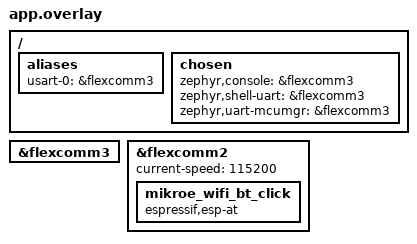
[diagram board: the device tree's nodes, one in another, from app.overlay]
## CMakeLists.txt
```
# SPDX-License-Identifier: Apache-2.0

add_compile_definitions(IS_ZEPHYR)

cmake_minimum_required(VERSION 3.20.0)
find_package(Zephyr REQUIRED HINTS $ENV{ZEPHYR_BASE})
project(dhcpv4_client)

file(GLOB_RECURSE app_sources src/*.c)

target_sources(app PRIVATE ${app_sources})

target_include_directories(app PRIVATE
    ${CMAKE_CURRENT_SOURCE_DIR}/src
    ${CMAKE_CURRENT_SOURCE_DIR}/src/common
    ${CMAKE_CURRENT_SOURCE_DIR}/src/pufcaller
    ${CMAKE_CURRENT_SOURCE_DIR}/src/pufcaller/crosscon_hv
    ${CMAKE_CURRENT_SOURCE_DIR}/src/pufcaller/crosscon_hv/crosscon_hv_tee
)

# Optional: define HAS_LOCAL_WIFI_CONFIG if wifi_config_local.h exists
if(EXISTS "${CMAKE_CURRENT_SOURCE_DIR}/src/wifi_config_local.h")
    add_compile_definitions(HAS_LOCAL_WIFI_CONFIG=1)
endif()
```

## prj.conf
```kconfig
# Kernel options
# CONFIG_MAIN_STACK_SIZE=16384
CONFIG_MAIN_STACK_SIZE=8192
CONFIG_ENTROPY_GENERATOR=y
CONFIG_INIT_STACKS=y
# CONFIG_COMMON_LIBC_MALLOC_ARENA_SIZE=8192
CONFIG_COMMON_LIBC_MALLOC_ARENA_SIZE=4096

# General config
CONFIG_NEWLIB_LIBC=y

# Networking config
CONFIG_NETWORKING=y
CONFIG_NET_IPV6=n
CONFIG_NET_IPV4=y
CONFIG_NET_ARP=y
CONFIG_NET_UDP=y
CONFIG_NET_TCP=y
CONFIG_NET_DHCPV4=y
CONFIG_NET_DHCPV4_OPTION_CALLBACKS=y

CONFIG_NET_MGMT=y
CONFIG_NET_MGMT_EVENT=y
CONFIG_NET_MGMT_EVENT_INFO=y

# Network debug config
CONFIG_LOG=y
CONFIG_NET_LOG=n
CONFIG_NET_SOCKETS_LOG_LEVEL_DBG=n
CONFIG_NET_HTTP_LOG_LEVEL_DBG=n
CONFIG_NET_IPV6_LOG_LEVEL_DBG=n
CONFIG_NET_IPV6_ND_LOG_LEVEL_DBG=n

CONFIG_SLIP_STATISTICS=n
CONFIG_NET_SHELL=n

# WiFi
CONFIG_WIFI=y
CONFIG_WIFI_ESP_AT=y
CONFIG_WIFI_ESP_AT_VERSION_2_0=y
CONFIG_NET_L2_WIFI_MGMT=y

# Sockets
CONFIG_NET_SOCKETS=y
CONFIG_ZVFS_POLL_MAX=4
CONFIG_POSIX_API=y

# TLS configuration
CONFIG_WOLFSSL=y
CONFIG_WOLFSSL_BUILTIN=y

# Debug
# CONFIG_LOG_DEFAULT_LEVEL=4
# CONFIG_KERNEL_LOG_LEVEL_OFF=y

# ## UART log backend
# CONFIG_LOG_BACKEND_UART=y
```

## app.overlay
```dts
/ {
	aliases{
		usart-0 = &flexcomm3;
	};

	chosen {
		zephyr,console = &flexcomm3;
		zephyr,shell-uart = &flexcomm3;
		zephyr,uart-mcumgr = &flexcomm3;
	};
};

&flexcomm3 {
	status = "okay";
};

&flexcomm2 {
	status = "okay";
	current-speed = <115200>;

	mikroe_wifi_bt_click {
		compatible = "espressif,esp-at";
		status = "okay";
	};
};
```

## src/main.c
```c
/* Networking DHCPv4 client */

/*
 * Copyright (c) 2025 3mdeb Sp z o.o.
 *
 * SPDX-License-Identifier: Apache-2.0
 */

#include "pufcaller/pufcaller.h"
#include <stdint.h>
#include <string.h>
#include <zephyr/logging/log.h>

LOG_MODULE_REGISTER(MAIN);

#include <zephyr/kernel.h>
#include <zephyr/linker/sections.h>
#include <stdio.h>

#include <zephyr/net/net_context.h>
#include <zephyr/net/net_core.h>
#include <zephyr/net/net_if.h>
#include <zephyr/net/net_mgmt.h>

#include <zephyr/net/wifi.h>
#include <zephyr/net/wifi_mgmt.h>

/* socket */
#include <zephyr/net/net_ip.h>
#include <zephyr/net/socket.h>

/* pufcaller */
#include "pufcaller/pufcaller.h"
#include "common/challenge.h"

/* SSL */
#ifndef WOLFSSL_USER_SETTINGS
    #include <wolfssl/options.h>
#endif
#include <wolfssl/ssl.h>
#include "ssl_certs.h"
#define HEAP_HINT  NULL

#define DHCP_OPTION_NTP (42)
#define MACSTR "%02X:%02X:%02X:%02X:%02X:%02X"

static uint8_t ntp_server[4];

static struct net_mgmt_event_callback mgmt_cb;

static struct net_dhcpv4_option_callback dhcp_cb;

func_call_t        initCh;
func_call_t        commCh;
func_call_t        proofsCh;

/*********** Socket start ***********/

#define SERVER_ADDR  "192.168.10.139"
#define SERVER_PORT  12345

/* DO NOT use this in production. You should implement a way
 * to get the current date. */
static int verifyIgnoreDateError(int preverify, WOLFSSL_X509_STORE_CTX* store)
{
    if (store->error == ASN_BEFORE_DATE_E)
        return 1; /* override error */
    else
        return preverify;
}

static int test_socket_connection(void) {
  struct sockaddr_in servAddr;
  int                ret;
  int                sock;
  char               buff[256];
  size_t             len;
  const char msg[] = "Hello from Zephyr!\n";
  char               wolfsslErrorStr[80];

  /* declare wolfSSL objects */
  WOLFSSL_CTX* ctx;
  WOLFSSL*     ssl;
  WOLFSSL_CIPHER* cipher;

  LOG_INF("Creating socket...");

  /* Create a socket that uses an internet IPv4 address,
   * Sets the socket to be stream based (TCP) */
	sock = socket(AF_INET, SOCK_STREAM, IPPROTO_TCP);

	if (sock < 0) {
		LOG_ERR("Failed to create HTTP socket (%d)", -errno);
	}

  LOG_INF("Socket created successfuly");

  /* Initialize the server address struct with zeros */
	memset(&servAddr, 0, sizeof(servAddr));
  LOG_DBG("memset");

  /* Fill in the server address */
  servAddr.sin_family = AF_INET;             /* using IPv4      */
  servAddr.sin_port   = htons(SERVER_PORT);  /* on SERVER_PORT  */
  LOG_DBG("server settings");

	if (inet_pton(AF_INET, SERVER_ADDR, &servAddr.sin_addr) != 1) {
	  LOG_ERR("Invalid server address");
	  ret = -1;
	}

  /* Connect to the server */
  LOG_INF("Connecting to the server...");
  if ((ret = connect(sock, (struct sockaddr*) &servAddr, sizeof(servAddr)))
       == -1) {
      LOG_ERR("Failed to connect");
      goto end;
  }

  /*---------------------------------*/
  /* Start of wolfSSL initialization and configuration */
  /*---------------------------------*/
  /* Initialize wolfSSL */
  LOG_DBG("wolfssl init");
  if ((ret = wolfSSL_Init()) != WOLFSSL_SUCCESS) {
      fprintf(stderr, "ERROR: Failed to initialize the library\n");
      goto socket_cleanup;
  }

#ifdef DEBUG_WOLFSSL
    wolfSSL_Debugging_ON();
#endif

  LOG_DBG("wolfssl ctx");
  /* Create and initialize WOLFSSL_CTX */
#ifdef USE_TLSV13
  LOG_DBG("Using TLS v1.3");
  ctx = wolfSSL_CTX_new_ex(wolfTLSv1_3_client_method_ex(HEAP_HINT), HEAP_HINT);
#else
  LOG_INF("Using TLS v1.2");
  ctx = wolfSSL_CTX_new_ex(wolfTLSv1_2_client_method_ex(HEAP_HINT), HEAP_HINT);
#endif
  if (ctx == NULL) {
    LOG_ERR("Failed to create WOLFSSL_CTX");
    ret = -1;
    goto socket_cleanup;
  }

  LOG_INF("Setting up cipher list...");
  if (wolfSSL_CTX_set_cipher_list(ctx, "ECDHE-ECDSA-AES256-GCM-SHA384") != WOLFSSL_SUCCESS) {
        fprintf(stderr, "Failed to set cipher list\n");
        ret = -1;
        goto ctx_cleanup;
    }

  /* Load client certificate into WOLFSSL_CTX */
  LOG_INF("Loading client certificate...");
  if ((ret = wolfSSL_CTX_use_certificate_buffer(ctx, client_cert_der,
               client_cert_der_len, WOLFSSL_FILETYPE_ASN1)) != WOLFSSL_SUCCESS) {
    LOG_ERR("Failed to load client certificate.");
    goto ctx_cleanup;
  }

  /* Load client key into WOLFSSL_CTX */
  LOG_INF("Loading client key...");
  if ((ret = wolfSSL_CTX_use_PrivateKey_buffer(ctx, client_key_der,
               client_key_der_len, WOLFSSL_FILETYPE_ASN1)) != WOLFSSL_SUCCESS) {
    LOG_ERR("Failed to load client key.");
    goto ctx_cleanup;
  }

  /* Load CA certificate into WOLFSSL_CTX for validating peer */
  LOG_INF("Loading CA certificate...");
  if ((ret = wolfSSL_CTX_load_verify_buffer_ex(ctx, ca_cert_der,
          ca_cert_der_len, WOLFSSL_FILETYPE_ASN1, 0,
          /* DO NOT use this in production. You should
           * implement a way to get the current date. */
          WOLFSSL_LOAD_FLAG_DATE_ERR_OKAY)) !=
          WOLFSSL_SUCCESS) {
    LOG_ERR("Failed to load CA certificate.");
    goto ctx_cleanup;
  }

  /* validate peer certificate */
  wolfSSL_CTX_set_verify(ctx,
    WOLFSSL_VERIFY_PEER|WOLFSSL_VERIFY_FAIL_IF_NO_PEER_CERT,
    verifyIgnoreDateError);

  /* Create a WOLFSSL object */
  LOG_INF("Creating SSL object...");
  if ((ssl = wolfSSL_new(ctx)) == NULL) {
      LOG_ERR("Failed to create WOLFSSL object");
      ret = -1;
      goto ctx_cleanup;
  }

  /* Attach wolfSSL to the socket */
  LOG_INF("Attaching SSL object...");
  if ((ret = wolfSSL_set_fd(ssl, sock)) != WOLFSSL_SUCCESS) {
      LOG_ERR("Failed to set the file descriptor");
      goto cleanup;
  }

  /* Connect to wolfSSL on the server side */
  LOG_INF("Connecting to server...");
  if ((ret = wolfSSL_connect(ssl)) != WOLFSSL_SUCCESS) {
      wolfSSL_ERR_error_string(wolfSSL_get_error(ssl, ret), wolfsslErrorStr);
      LOG_ERR("Failed to connect to server: %s", wolfsslErrorStr);
      goto cleanup;
  }

  cipher = wolfSSL_get_current_cipher(ssl);
  LOG_INF("SSL cipher suite is: %s", wolfSSL_CIPHER_get_name(cipher));

  if (initFunc(&initCh, PUF_TA_INIT_FUNC_ID, pattern_init_commit))
    LOG_ERR("Failed to allocate memory for the init...");
  LOG_DBG("Receiving init");
  if (recChallenge(ssl, &initCh))
    LOG_ERR("Failed to receive init!");

  if (initFunc(&commCh, PUF_TA_GET_COMMITMENT_FUNC_ID, pattern_init_commit))
    LOG_ERR("Failed to allocate memory for the commitment...");
  LOG_DBG("Receiving commitment");
  if (recChallenge(ssl, &commCh))
    LOG_ERR("Failed to receive commitment!");

  if (initFunc(&proofsCh, PUF_TA_GET_ZK_PROOFS_FUNC_ID, pattern_proofs))
    LOG_ERR("Failed to allocate memory for the proofs...");
  LOG_DBG("Receiving proofs");
  if (recChallenge(ssl, &proofsCh))
    LOG_ERR("Failed to receive proofs!");

  LOG_INF("Challenging the PUF");
  challenge_puf(&initCh, &commCh, &proofsCh);

  LOG_INF("Sending init response");
  if (sendResponse(ssl, &initCh)) {
    LOG_INF("Sending init response failed");
    goto cleanup;
  }

  LOG_INF("Sending commitment response");
  if (sendResponse(ssl, &commCh)) {
    LOG_INF("Sending commitment response failed");
    goto cleanup;
  }

  LOG_INF("Sending proofs response");
  if (sendResponse(ssl, &proofsCh)) {
    LOG_INF("Sending proofs response failed");
    goto cleanup;
  }

  /* Construct a message for the server */
  LOG_INF("Constructing message for server...");
  memset(buff, 0, sizeof(buff));
  memcpy(buff, msg, sizeof(msg));
  len = strnlen(buff, sizeof(buff));

  /* Send the message to the server */
  LOG_INF("Sending message to server...");
  if ((ret = wolfSSL_write(ssl, buff, len)) != len) {
      LOG_ERR("Failed to write entire message");
      LOG_ERR("%d bytes of %d bytes were sent", ret, (int) len);
      goto cleanup;
  }

  /* Read the server data into our buff array */
  LOG_INF("Reading message from server...");
  memset(buff, 0, sizeof(buff));
  if ((ret = wolfSSL_read(ssl, buff, sizeof(buff)-1)) == -1) {
      LOG_ERR("Failed to read from server");
      goto cleanup;
  }

  /* Print to stdout any data the server sends */
  LOG_INF("Received from server: %s", buff);

  /* Bidirectional shutdown */
  LOG_INF("Starting SSL shutdown...");
  while (wolfSSL_shutdown(ssl) == WOLFSSL_SHUTDOWN_NOT_DONE) {
      LOG_INF("SSL shutdown not complete");
  }

  LOG_INF("SSL shutdown complete");

  ret = 0;

  /* Cleanup and return */
cleanup:
  wolfSSL_free(ssl);      /* Free the wolfSSL object                  */
  freeFunc(&initCh);
  freeFunc(&commCh);
  freeFunc(&proofsCh);
ctx_cleanup:
  wolfSSL_CTX_free(ctx);  /* Free the wolfSSL context object          */
  wolfSSL_Cleanup();      /* Cleanup the wolfSSL environment          */
socket_cleanup:
  close(sock)    ;          /* Close the connection to the server       */
end:
  LOG_DBG("ret: %d", ret);
  return ret;               /* Return reporting a success               */
}

/*********** Socket end ***********/

/* Wi-Fi Configuration */
#include "wifi_config.h"
#define WIFI_SECURITY_TYPE WIFI_SECURITY_TYPE_PSK

#define NET_EVENT_WIFI_MASK                                                    \
  (NET_EVENT_WIFI_CONNECT_RESULT | NET_EVENT_WIFI_DISCONNECT_RESULT |          \
   NET_EVENT_WIFI_AP_ENABLE_RESULT | NET_EVENT_WIFI_AP_DISABLE_RESULT |        \
   NET_EVENT_WIFI_AP_STA_CONNECTED | NET_EVENT_WIFI_AP_STA_DISCONNECTED)

static struct net_if *sta_iface;
static struct net_mgmt_event_callback cb;

static void wifi_event_handler(struct net_mgmt_event_callback *cb,
                               uint32_t mgmt_event, struct net_if *iface) {
  switch (mgmt_event) {
  case NET_EVENT_WIFI_CONNECT_RESULT: {
    LOG_INF("Connected to %s", WIFI_SSID);
    break;
  }
  case NET_EVENT_WIFI_DISCONNECT_RESULT: {
    LOG_INF("Disconnected from %s", WIFI_SSID);
    break;
  }
  case NET_EVENT_WIFI_AP_ENABLE_RESULT: {
    LOG_INF("AP Mode is enabled. Waiting for station to connect");
    break;
  }
  case NET_EVENT_WIFI_AP_DISABLE_RESULT: {
    LOG_INF("AP Mode is disabled.");
    break;
  }
  case NET_EVENT_WIFI_AP_STA_CONNECTED: {
    struct wifi_ap_sta_info *sta_info = (struct wifi_ap_sta_info *)cb->info;

    LOG_INF("station: " MACSTR " joined ", sta_info->mac[0], sta_info->mac[1],
            sta_info->mac[2], sta_info->mac[3], sta_info->mac[4],
            sta_info->mac[5]);
    break;
  }
  case NET_EVENT_WIFI_AP_STA_DISCONNECTED: {
    struct wifi_ap_sta_info *sta_info = (struct wifi_ap_sta_info *)cb->info;

    LOG_INF("station: " MACSTR " leave ", sta_info->mac[0], sta_info->mac[1],
            sta_info->mac[2], sta_info->mac[3], sta_info->mac[4],
            sta_info->mac[5]);
    break;
  }
  default:
    break;
  }
}

static void start_dhcpv4_client(struct net_if *iface, void *user_data) {
  ARG_UNUSED(user_data);

  LOG_INF("Start on %s: index=%d", net_if_get_device(iface)->name,
          net_if_get_by_iface(iface));
  net_dhcpv4_start(iface);
}

static void handler(struct net_mgmt_event_callback *cb, uint32_t mgmt_event,
                    struct net_if *iface) {
  int i = 0;

  if (mgmt_event != NET_EVENT_IPV4_ADDR_ADD) {
    return;
  }

  for (i = 0; i < NET_IF_MAX_IPV4_ADDR; i++) {
    char buf[NET_IPV4_ADDR_LEN];

    if (iface->config.ip.ipv4->unicast[i].ipv4.addr_type != NET_ADDR_DHCP) {
      continue;
    }

    LOG_INF(
        "   Address[%d]: %s", net_if_get_by_iface(iface),
        net_addr_ntop(AF_INET,
                      &iface->config.ip.ipv4->unicast[i].ipv4.address.in_addr,
                      buf, sizeof(buf)));
    LOG_INF("    Subnet[%d]: %s", net_if_get_by_iface(iface),
            net_addr_ntop(AF_INET, &iface->config.ip.ipv4->unicast[i].netmask,
                          buf, sizeof(buf)));
    LOG_INF(
        "    Router[%d]: %s", net_if_get_by_iface(iface),
        net_addr_ntop(AF_INET, &iface->config.ip.ipv4->gw, buf, sizeof(buf)));
    LOG_INF("Lease time[%d]: %u seconds", net_if_get_by_iface(iface),
            iface->config.dhcpv4.lease_time);
  }
}

static void option_handler(struct net_dhcpv4_option_callback *cb, size_t length,
                           enum net_dhcpv4_msg_type msg_type,
                           struct net_if *iface) {
  char buf[NET_IPV4_ADDR_LEN];

  LOG_INF("DHCP Option %d: %s", cb->option,
          net_addr_ntop(AF_INET, cb->data, buf, sizeof(buf)));
}

static int connect_to_wifi(void) {
  struct wifi_connect_req_params wifi_params = {
      .ssid = WIFI_SSID,
      .ssid_length = strlen(WIFI_SSID),
      .psk = WIFI_PASSWORD,
      .psk_length = strlen(WIFI_PASSWORD),
      .security = WIFI_SECURITY_TYPE,
  };
  LOG_INF("Connecting to Wi-Fi network %s...", WIFI_SSID);

  sta_iface = net_if_get_wifi_sta();
  int ret;
  ret = net_mgmt(NET_REQUEST_WIFI_CONNECT, sta_iface, &wifi_params,
                 sizeof(wifi_params));
  if (ret != 0) {
    LOG_ERR("Failed to connect to Wi-Fi network: %d", ret);
    return ret;
  }

  LOG_INF("Connected to Wi-Fi network %s", WIFI_SSID);

  return 0;
}

static void wait_for_dhcp(void) {
  struct in_addr *addr;

  do {
    addr = net_if_ipv4_get_global_addr(sta_iface, NET_ADDR_ANY_STATE);
    if (addr) {
        LOG_INF("Address is assigned");
        break;
    }
    LOG_INF("Waiting for address to be assigned...");
    sleep(1);
  } while (1);
}


int main(void) {
#ifdef IS_ZEPHYR
  LOG_INF("IS_ZEPHYR defined");
#endif
  LOG_INF("Hello in WiFi App!");
  net_mgmt_init_event_callback(&cb, wifi_event_handler, NET_EVENT_WIFI_MASK);
  net_mgmt_add_event_callback(&cb);

  net_mgmt_init_event_callback(&mgmt_cb, handler, NET_EVENT_IPV4_ADDR_ADD);
  net_mgmt_add_event_callback(&mgmt_cb);
  net_dhcpv4_init_option_callback(&dhcp_cb, option_handler, DHCP_OPTION_NTP,
                                  ntp_server, sizeof(ntp_server));
  net_dhcpv4_add_option_callback(&dhcp_cb);

  connect_to_wifi();

  LOG_INF("Run dhcpv4 client");
  net_if_foreach(start_dhcpv4_client, NULL);

  wait_for_dhcp();

  test_socket_connection();

  return 0;
}
```

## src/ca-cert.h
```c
static const unsigned char ca_cert_der[] = {
  0x30, 0x82, 0x01, 0x8c, 0x30, 0x82, 0x01, 0x33, 0xa0, 0x03, 0x02, 0x01,
  0x02, 0x02, 0x14, 0x67, 0xae, 0x58, 0x51, 0xd0, 0x3f, 0x91, 0xc0, 0x40,
  0xbb, 0x7a, 0x3b, 0x3d, 0x2c, 0x2e, 0x7d, 0x90, 0xe4, 0x00, 0x15, 0x30,
  0x0a, 0x06, 0x08, 0x2a, 0x86, 0x48, 0xce, 0x3d, 0x04, 0x03, 0x02, 0x30,
  0x14, 0x31, 0x12, 0x30, 0x10, 0x06, 0x03, 0x55, 0x04, 0x03, 0x0c, 0x09,
  0x4d, 0x79, 0x20, 0x45, 0x43, 0x43, 0x20, 0x43, 0x41, 0x30, 0x1e, 0x17,
  0x0d, 0x32, 0x35, 0x30, 0x37, 0x31, 0x30, 0x31, 0x32, 0x33, 0x35, 0x30,
  0x34, 0x5a, 0x17, 0x0d, 0x33, 0x35, 0x30, 0x37, 0x30, 0x38, 0x31, 0x32,
  0x33, 0x35, 0x30, 0x34, 0x5a, 0x30, 0x14, 0x31, 0x12, 0x30, 0x10, 0x06,
  0x03, 0x55, 0x04, 0x03, 0x0c, 0x09, 0x4d, 0x79, 0x20, 0x45, 0x43, 0x43,
  0x20, 0x43, 0x41, 0x30, 0x59, 0x30, 0x13, 0x06, 0x07, 0x2a, 0x86, 0x48,
  0xce, 0x3d, 0x02, 0x01, 0x06, 0x08, 0x2a, 0x86, 0x48, 0xce, 0x3d, 0x03,
  0x01, 0x07, 0x03, 0x42, 0x00, 0x04, 0x7e, 0x4f, 0xda, 0x09, 0x55, 0x1d,
  0x93, 0x10, 0xce, 0x9b, 0x1a, 0x2b, 0xd6, 0xa3, 0xe8, 0x23, 0x68, 0xda,
  0xf4, 0x63, 0x91, 0xbd, 0x87, 0x7b, 0xf7, 0x73, 0x43, 0xd4, 0x1d, 0xe1,
  0x37, 0xf0, 0xd7, 0x50, 0x30, 0xdc, 0xdb, 0x73, 0xbe, 0x1e, 0x60, 0x9c,
  0xc7, 0x3a, 0x99, 0x83, 0x10, 0xcb, 0xcc, 0xec, 0xf5, 0x9c, 0xbd, 0xce,
  0xd1, 0xc5, 0x1b, 0x83, 0x99, 0xc1, 0xc2, 0x11, 0x27, 0x44, 0xa3, 0x63,
  0x30, 0x61, 0x30, 0x1f, 0x06, 0x03, 0x55, 0x1d, 0x23, 0x04, 0x18, 0x30,
  0x16, 0x80, 0x14, 0x0b, 0x0a, 0x0b, 0xab, 0x79, 0x1c, 0x14, 0x69, 0x2e,
  0x74, 0x50, 0x01, 0xd1, 0x1d, 0x82, 0x67, 0xb0, 0x61, 0xed, 0x42, 0x30,
  0x0f, 0x06, 0x03, 0x55, 0x1d, 0x13, 0x01, 0x01, 0xff, 0x04, 0x05, 0x30,
  0x03, 0x01, 0x01, 0xff, 0x30, 0x0e, 0x06, 0x03, 0x55, 0x1d, 0x0f, 0x01,
  0x01, 0xff, 0x04, 0x04, 0x03, 0x02, 0x01, 0x06, 0x30, 0x1d, 0x06, 0x03,
  0x55, 0x1d, 0x0e, 0x04, 0x16, 0x04, 0x14, 0x0b, 0x0a, 0x0b, 0xab, 0x79,
  0x1c, 0x14, 0x69, 0x2e, 0x74, 0x50, 0x01, 0xd1, 0x1d, 0x82, 0x67, 0xb0,
  0x61, 0xed, 0x42, 0x30, 0x0a, 0x06, 0x08, 0x2a, 0x86, 0x48, 0xce, 0x3d,
  0x04, 0x03, 0x02, 0x03, 0x47, 0x00, 0x30, 0x44, 0x02, 0x20, 0x22, 0xca,
  0xf9, 0x7c, 0x09, 0x66, 0x9b, 0x9f, 0xe4, 0x4b, 0xcb, 0x28, 0xeb, 0x53,
  0x3d, 0x8e, 0x5d, 0x51, 0xe7, 0x3e, 0xbb, 0x2d, 0xba, 0xa7, 0x89, 0x42,
  0x6f, 0x7d, 0xba, 0x19, 0x4c, 0x9c, 0x02, 0x20, 0x69, 0x94, 0xc1, 0xa6,
  0x1a, 0xac, 0x20, 0x99, 0x94, 0x26, 0xe0, 0x02, 0x6b, 0xaf, 0xc9, 0xd7,
  0x74, 0x03, 0xd1, 0x20, 0xec, 0x6c, 0xcb, 0x48, 0xd8, 0x1d, 0xcb, 0x97,
  0x83, 0x1e, 0x67, 0x0e
};

static const unsigned int ca_cert_der_len = sizeof(ca_cert_der);
```

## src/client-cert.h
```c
static const unsigned char client_cert_der[] = {
  0x30, 0x82, 0x03, 0x5e, 0x30, 0x82, 0x03, 0x04, 0xa0, 0x03, 0x02, 0x01,
  0x02, 0x02, 0x14, 0x59, 0xe6, 0x5a, 0x21, 0xe0, 0xc4, 0x3f, 0x67, 0x06,
  0x9b, 0x21, 0x43, 0x3e, 0x76, 0xca, 0xf0, 0x3f, 0x68, 0x5b, 0x53, 0x30,
  0x0a, 0x06, 0x08, 0x2a, 0x86, 0x48, 0xce, 0x3d, 0x04, 0x03, 0x02, 0x30,
  0x81, 0x8d, 0x31, 0x0b, 0x30, 0x09, 0x06, 0x03, 0x55, 0x04, 0x06, 0x13,
  0x02, 0x55, 0x53, 0x31, 0x0f, 0x30, 0x0d, 0x06, 0x03, 0x55, 0x04, 0x08,
  0x0c, 0x06, 0x4f, 0x72, 0x65, 0x67, 0x6f, 0x6e, 0x31, 0x0e, 0x30, 0x0c,
  0x06, 0x03, 0x55, 0x04, 0x07, 0x0c, 0x05, 0x53, 0x61, 0x6c, 0x65, 0x6d,
  0x31, 0x13, 0x30, 0x11, 0x06, 0x03, 0x55, 0x04, 0x0a, 0x0c, 0x0a, 0x43,
  0x6c, 0x69, 0x65, 0x6e, 0x74, 0x20, 0x45, 0x43, 0x43, 0x31, 0x0d, 0x30,
  0x0b, 0x06, 0x03, 0x55, 0x04, 0x0b, 0x0c, 0x04, 0x46, 0x61, 0x73, 0x74,
  0x31, 0x18, 0x30, 0x16, 0x06, 0x03, 0x55, 0x04, 0x03, 0x0c, 0x0f, 0x77,
  0x77, 0x77, 0x2e, 0x77, 0x6f, 0x6c, 0x66, 0x73, 0x73, 0x6c, 0x2e, 0x63,
  0x6f, 0x6d, 0x31, 0x1f, 0x30, 0x1d, 0x06, 0x09, 0x2a, 0x86, 0x48, 0x86,
  0xf7, 0x0d, 0x01, 0x09, 0x01, 0x16, 0x10, 0x69, 0x6e, 0x66, 0x6f, 0x40,
  0x77, 0x6f, 0x6c, 0x66, 0x73, 0x73, 0x6c, 0x2e, 0x63, 0x6f, 0x6d, 0x30,
  0x1e, 0x17, 0x0d, 0x32, 0x32, 0x31, 0x32, 0x31, 0x36, 0x32, 0x31, 0x31,
  0x37, 0x34, 0x39, 0x5a, 0x17, 0x0d, 0x32, 0x35, 0x30, 0x39, 0x31, 0x31,
  0x32, 0x31, 0x31, 0x37, 0x34, 0x39, 0x5a, 0x30, 0x81, 0x8d, 0x31, 0x0b,
  0x30, 0x09, 0x06, 0x03, 0x55, 0x04, 0x06, 0x13, 0x02, 0x55, 0x53, 0x31,
  0x0f, 0x30, 0x0d, 0x06, 0x03, 0x55, 0x04, 0x08, 0x0c, 0x06, 0x4f, 0x72,
  0x65, 0x67, 0x6f, 0x6e, 0x31, 0x0e, 0x30, 0x0c, 0x06, 0x03, 0x55, 0x04,
  0x07, 0x0c, 0x05, 0x53, 0x61, 0x6c, 0x65, 0x6d, 0x31, 0x13, 0x30, 0x11,
  0x06, 0x03, 0x55, 0x04, 0x0a, 0x0c, 0x0a, 0x43, 0x6c, 0x69, 0x65, 0x6e,
  0x74, 0x20, 0x45, 0x43, 0x43, 0x31, 0x0d, 0x30, 0x0b, 0x06, 0x03, 0x55,
  0x04, 0x0b, 0x0c, 0x04, 0x46, 0x61, 0x73, 0x74, 0x31, 0x18, 0x30, 0x16,
  0x06, 0x03, 0x55, 0x04, 0x03, 0x0c, 0x0f, 0x77, 0x77, 0x77, 0x2e, 0x77,
  0x6f, 0x6c, 0x66, 0x73, 0x73, 0x6c, 0x2e, 0x63, 0x6f, 0x6d, 0x31, 0x1f,
  0x30, 0x1d, 0x06, 0x09, 0x2a, 0x86, 0x48, 0x86, 0xf7, 0x0d, 0x01, 0x09,
  0x01, 0x16, 0x10, 0x69, 0x6e, 0x66, 0x6f, 0x40, 0x77, 0x6f, 0x6c, 0x66,
  0x73, 0x73, 0x6c, 0x2e, 0x63, 0x6f, 0x6d, 0x30, 0x59, 0x30, 0x13, 0x06,
  0x07, 0x2a, 0x86, 0x48, 0xce, 0x3d, 0x02, 0x01, 0x06, 0x08, 0x2a, 0x86,
  0x48, 0xce, 0x3d, 0x03, 0x01, 0x07, 0x03, 0x42, 0x00, 0x04, 0x55, 0xbf,
  0xf4, 0x0f, 0x44, 0x50, 0x9a, 0x3d, 0xce, 0x9b, 0xb7, 0xf0, 0xc5, 0x4d,
  0xf5, 0x70, 0x7b, 0xd4, 0xec, 0x24, 0x8e, 0x19, 0x80, 0xec, 0x5a, 0x4c,
  0xa2, 0x24, 0x03, 0x62, 0x2c, 0x9b, 0xda, 0xef, 0xa2, 0x35, 0x12, 0x43,
  0x84, 0x76, 0x16, 0xc6, 0x56, 0x95, 0x06, 0xcc, 0x01, 0xa9, 0xbd, 0xf6,
  0x75, 0x1a, 0x42, 0xf7, 0xbd, 0xa9, 0xb2, 0x36, 0x22, 0x5f, 0xc7, 0x5d,
  0x7f, 0xb4, 0xa3, 0x82, 0x01, 0x3e, 0x30, 0x82, 0x01, 0x3a, 0x30, 0x1d,
  0x06, 0x03, 0x55, 0x1d, 0x0e, 0x04, 0x16, 0x04, 0x14, 0xeb, 0xd4, 0x4b,
  0x59, 0x6b, 0x95, 0x61, 0x3f, 0x51, 0x57, 0xb6, 0x04, 0x4d, 0x89, 0x41,
  0x88, 0x44, 0x5c, 0xab, 0xf2, 0x30, 0x81, 0xcd, 0x06, 0x03, 0x55, 0x1d,
  0x23, 0x04, 0x81, 0xc5, 0x30, 0x81, 0xc2, 0x80, 0x14, 0xeb, 0xd4, 0x4b,
  0x59, 0x6b, 0x95, 0x61, 0x3f, 0x51, 0x57, 0xb6, 0x04, 0x4d, 0x89, 0x41,
  0x88, 0x44, 0x5c, 0xab, 0xf2, 0xa1, 0x81, 0x93, 0xa4, 0x81, 0x90, 0x30,
  0x81, 0x8d, 0x31, 0x0b, 0x30, 0x09, 0x06, 0x03, 0x55, 0x04, 0x06, 0x13,
  0x02, 0x55, 0x53, 0x31, 0x0f, 0x30, 0x0d, 0x06, 0x03, 0x55, 0x04, 0x08,
  0x0c, 0x06, 0x4f, 0x72, 0x65, 0x67, 0x6f, 0x6e, 0x31, 0x0e, 0x30, 0x0c,
  0x06, 0x03, 0x55, 0x04, 0x07, 0x0c, 0x05, 0x53, 0x61, 0x6c, 0x65, 0x6d,
  0x31, 0x13, 0x30, 0x11, 0x06, 0x03, 0x55, 0x04, 0x0a, 0x0c, 0x0a, 0x43,
  0x6c, 0x69, 0x65, 0x6e, 0x74, 0x20, 0x45, 0x43, 0x43, 0x31, 0x0d, 0x30,
  0x0b, 0x06, 0x03, 0x55, 0x04, 0x0b, 0x0c, 0x04, 0x46, 0x61, 0x73, 0x74,
  0x31, 0x18, 0x30, 0x16, 0x06, 0x03, 0x55, 0x04, 0x03, 0x0c, 0x0f, 0x77,
  0x77, 0x77, 0x2e, 0x77, 0x6f, 0x6c, 0x66, 0x73, 0x73, 0x6c, 0x2e, 0x63,
  0x6f, 0x6d, 0x31, 0x1f, 0x30, 0x1d, 0x06, 0x09, 0x2a, 0x86, 0x48, 0x86,
  0xf7, 0x0d, 0x01, 0x09, 0x01, 0x16, 0x10, 0x69, 0x6e, 0x66, 0x6f, 0x40,
  0x77, 0x6f, 0x6c, 0x66, 0x73, 0x73, 0x6c, 0x2e, 0x63, 0x6f, 0x6d, 0x82,
  0x14, 0x59, 0xe6, 0x5a, 0x21, 0xe0, 0xc4, 0x3f, 0x67, 0x06, 0x9b, 0x21,
  0x43, 0x3e, 0x76, 0xca, 0xf0, 0x3f, 0x68, 0x5b, 0x53, 0x30, 0x0c, 0x06,
  0x03, 0x55, 0x1d, 0x13, 0x04, 0x05, 0x30, 0x03, 0x01, 0x01, 0xff, 0x30,
  0x1c, 0x06, 0x03, 0x55, 0x1d, 0x11, 0x04, 0x15, 0x30, 0x13, 0x82, 0x0b,
  0x65, 0x78, 0x61, 0x6d, 0x70, 0x6c, 0x65, 0x2e, 0x63, 0x6f, 0x6d, 0x87,
  0x04, 0x7f, 0x00, 0x00, 0x01, 0x30, 0x1d, 0x06, 0x03, 0x55, 0x1d, 0x25,
  0x04, 0x16, 0x30, 0x14, 0x06, 0x08, 0x2b, 0x06, 0x01, 0x05, 0x05, 0x07,
  0x03, 0x01, 0x06, 0x08, 0x2b, 0x06, 0x01, 0x05, 0x05, 0x07, 0x03, 0x02,
  0x30, 0x0a, 0x06, 0x08, 0x2a, 0x86, 0x48, 0xce, 0x3d, 0x04, 0x03, 0x02,
  0x03, 0x48, 0x00, 0x30, 0x45, 0x02, 0x20, 0x70, 0xf8, 0x0e, 0x6e, 0x91,
  0xc9, 0x09, 0x77, 0x25, 0x8c, 0xba, 0x99, 0x6d, 0x54, 0x2d, 0xa8, 0x52,
  0x87, 0x17, 0x51, 0x24, 0x8b, 0x13, 0x92, 0x89, 0x7d, 0xc9, 0xba, 0xb4,
  0x43, 0x2e, 0x48, 0x02, 0x21, 0x00, 0xab, 0x41, 0x13, 0x3a, 0xd5, 0xeb,
  0x68, 0x66, 0x36, 0x56, 0x7c, 0x75, 0x5d, 0x37, 0xe3, 0xf6, 0x27, 0x7f,
  0x54, 0xd5, 0x42, 0x80, 0x29, 0xdb, 0xe5, 0x9b, 0x16, 0x8a, 0xd3, 0xc2,
  0xad, 0xd6
};

static const unsigned int client_cert_der_len = sizeof(client_cert_der);
```

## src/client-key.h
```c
static const unsigned char client_key_der[] = {
  0x30, 0x81, 0x87, 0x02, 0x01, 0x00, 0x30, 0x13, 0x06, 0x07, 0x2a, 0x86,
  0x48, 0xce, 0x3d, 0x02, 0x01, 0x06, 0x08, 0x2a, 0x86, 0x48, 0xce, 0x3d,
  0x03, 0x01, 0x07, 0x04, 0x6d, 0x30, 0x6b, 0x02, 0x01, 0x01, 0x04, 0x20,
  0x2b, 0xcf, 0x57, 0x84, 0xe0, 0x7b, 0xb7, 0x6f, 0x8c, 0xff, 0x8c, 0xe0,
  0xf0, 0x05, 0x77, 0x4e, 0xa3, 0x7f, 0x91, 0x90, 0xe2, 0x53, 0x64, 0x45,
  0x48, 0x33, 0x89, 0x2e, 0xaf, 0xeb, 0xd7, 0x11, 0xa1, 0x44, 0x03, 0x42,
  0x00, 0x04, 0x2f, 0xf7, 0x07, 0x9f, 0xee, 0x53, 0x95, 0xd3, 0x69, 0x22,
  0xe7, 0x8a, 0xf8, 0x81, 0x0a, 0xb5, 0xf5, 0x10, 0xdd, 0xab, 0x3e, 0xca,
  0x1d, 0xc1, 0x72, 0x8c, 0x9e, 0xa1, 0xab, 0x36, 0x48, 0x74, 0x44, 0x32,
  0x8b, 0xa7, 0x0b, 0xcb, 0xf6, 0x6c, 0xda, 0x30, 0x5f, 0xa6, 0x0f, 0xa9,
  0x1d, 0x28, 0x99, 0xb9, 0x95, 0x58, 0x15, 0x1f, 0x05, 0x13, 0xd5, 0x05,
  0x49, 0x8b, 0x9a, 0xb9, 0x61, 0x34
};

static const unsigned int client_key_der_len = sizeof(client_key_der);
```

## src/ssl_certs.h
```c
#include "ca-cert.h"
#include "client-cert.h"
#include "client-key.h"
```

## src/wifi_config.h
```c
#ifdef HAS_LOCAL_WIFI_CONFIG
  #include "wifi_config_local.h"
#else
  #include "wifi_config_default.h"
#endif
```
